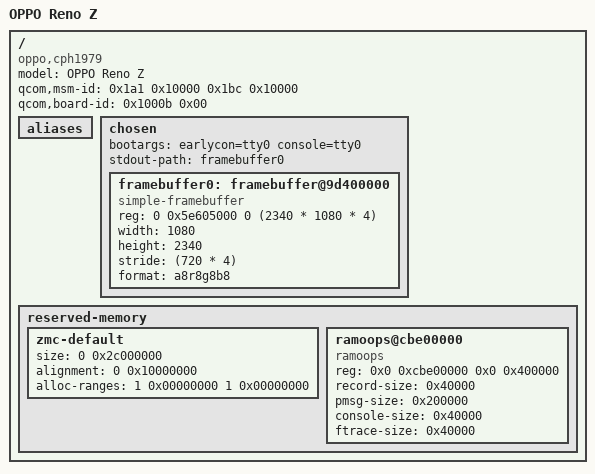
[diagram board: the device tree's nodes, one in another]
// SPDX-License-Identifier: GPL-2.0-only
/*
 * Copyright (c) 2021, Iskren Chernev <iskren.chernev@gmail.com>
 */

/dts-v1/;

#include "mt6779.dtsi"

/ {
	model = "OPPO Reno Z";
	compatible = "oppo,cph1979", "mediatek,mt6779";

	/* required for bootloader to select correct board */
	qcom,msm-id = <0x1a1 0x10000 0x1bc 0x10000>;
	qcom,board-id = <0x1000b 0x00>;

	aliases {
	};

	chosen {
		bootargs = "earlycon=tty0 console=tty0";

		#address-cells = <2>;
		#size-cells = <2>;
		ranges;

		stdout-path = "framebuffer0";

		framebuffer0: framebuffer@9d400000 {
			compatible = "simple-framebuffer";
			reg = <0 0x5e605000 0 (2340 * 1080 * 4)>;
			width = <1080>;
			height = <2340>;
			stride = <(720 * 4)>;
			format = "a8r8g8b8";
			status= "okay";
		};
	};

	reserved-memory {
	zmc-default {
		size = <0 0x2c000000>;
		alignment = <0 0x10000000>;
		alloc-ranges = <1 0x00000000 1 0x00000000>;
	};

		ramoops@cbe00000 {
			compatible = "ramoops";
			reg = <0x0 0xcbe00000 0x0 0x400000>;
			record-size = <0x40000>;
			pmsg-size = <0x200000>;
			console-size = <0x40000>;
			ftrace-size = <0x40000>;
		};
	};
};

